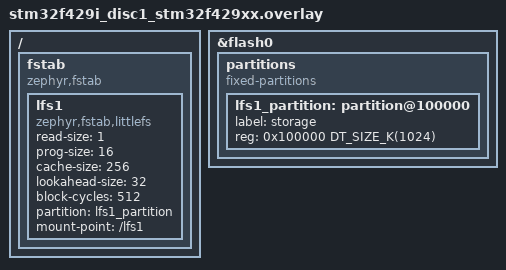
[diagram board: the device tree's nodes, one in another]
/*
 * Copyright (c) 2024 STMicroelectronics
 *
 * SPDX-License-Identifier: Apache-2.0
 */

/ {
	fstab {
		compatible = "zephyr,fstab";
		lfs1: lfs1 {
			compatible = "zephyr,fstab,littlefs";
			read-size = <1>;
			prog-size = <16>;
			cache-size = <256>;
			lookahead-size = <32>;
			block-cycles = <512>;
			partition = <&lfs1_partition>;
			mount-point = "/lfs1";
    };
	};
};

&flash0 {
	partitions {
		compatible = "fixed-partitions";
		#address-cells = <1>;
		#size-cells = <1>;

		/* Use second half of flash for the filesystem. */
		lfs1_partition: partition@100000 {
			label = "storage";
			reg = <0x100000 DT_SIZE_K(1024)>;
		};
	};
};
